# cslr_edc register map
Vendor: Texas Instruments
Peripheral module from a debugger description file.
Registers are 32-bit, read-only, reset 0x0 unless marked. A register's access mark holds for its fields unless they carry their own. Offsets are as the file gives them; lines under a group give offsets from that group; [hi:lo] are bit positions; {n}, {i} and the like mark numbered series; 'fields as' and 'values as' point back to an identical list; <NAME> marks a mode.

## EDC — Error Detection and Correction
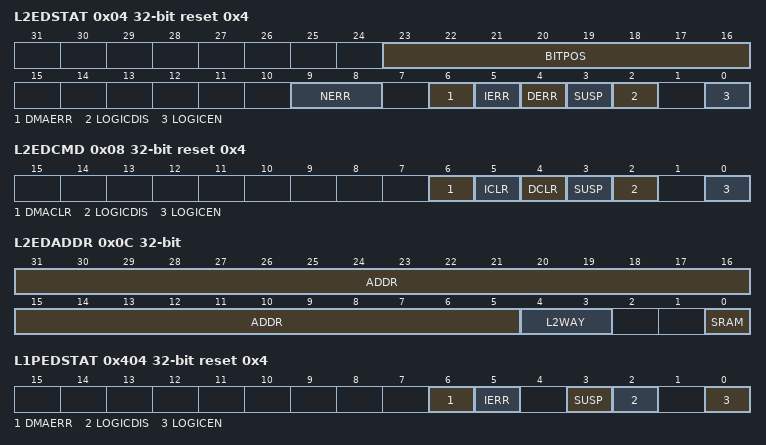
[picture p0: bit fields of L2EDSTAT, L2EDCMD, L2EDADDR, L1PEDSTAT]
0x04 L2EDSTAT reset 0x4 — L2 Error Detection Status Register
  [23:16] BITPOS — Position of single bit error 0 - 255
  [9:8] NERR — Number of bits in error
    0=1BIT (Single Bit Error); 1=2BIT (Double Bit Error); 3=PERROR (Error in the parity value (256-bit data is correct))
  [6] DMAERR — Parity error occurred during DMA Access?
    1=YES (Parity Error Occured during DMA Access); 0=NO (No Parity Error Occured during DMA Access)
  [5] IERR — Parity error occured during CPU/L1P access
    1=YES (Parity Error Occured during CPU/L1P Access); 0=NO (No Parity Error Occured during CPU/L1P Access)
  [4] DERR — Parity error occured during CPU/L1D data access
    1=YES (Parity Error Occured during CPU/L1D Data Access); 0=NO (No Parity Error Occured during CPU/L1D Data Access)
  [3] SUSP — EDC Parity generation logic suspended
    1=YES (EDC Logic Suspended?); 0=NO (EDC Logic Suspended?)
  [2] LOGICDIS — EDC Parity generation logic disable
    1=YES (EDC Logic Disabled); 0=NO (EDC Logic Disabled)
  [0] LOGICEN — EDC Parity generation logic enable
    1=YES (EDC Logic Enabled); 0=NO (EDC Logic Enabled)
0x08 L2EDCMD access per field reset 0x4 — L2 Error Detection Command Register
  [6] DMACLR wo — Clear Parity Error DMA Access Bit DMAERR
    1=CLR (Clear parity error CPU/L1P access bit IERR)
  [5] ICLR wo — Clear parity error CPU/L1P access bit IERR
    1=CLR (Clear parity error CPU/L1P access bit IERR)
  [4] DCLR wo — Clear CPU/L1D data access error bit DERR
    1=CLR (Clear parity error CPU/L1D data access bit DERR)
  [3] SUSP wo — Suspend EDC parity generation logic
    1=YES (Suspend EDC Logic)
  [2] LOGICDIS wo — Disable EDC parity generation logic
    1=YES (Disable EDC Logic)
  [0] LOGICEN wo — Enable EDC parity generation logic
    1=YES (Enable EDC Logic)
0x0C L2EDADDR — L2 Error Detection Address Register
  [31:5] ADDR — Address of the 256 bits in which a parity error occured (5 LSBs assumed to be 00000b)
  [4:3] L2WAY — The 'way' of L2 Cache the error occurred in.
    {v}=WAY{v} (v=0..3)
  [0] SRAM — Error Detected in L2 SRAM or L2 Cache
    0=L2CACHE (Error Detected in L2 Cache); 1=L2SRAM (Error Detected in L2 Memory)
0x10 L2EDEN0 rw — L2 Error Dection Enable Map 0 Register
  [31:0] EN — Enable Page 0 to 31 for L2 Error Detection UMAP0
    1=EN (Enable Page); 0=DIS (Disable Page)
0x14 L2EDEN1 rw — L2 Error Dection Enable Map 1 Register
  [31:0] EN — Enable Page 0 to 31 for L2 Error Detection UMAP1
    1=EN (Enable Page); 0=DIS (Disable Page)
0x18 L2EDCPEC access not given — L2 Error Detection - Correctable Parity Error Count
  [7:0] CNT — L2 EDC Correctable Error Count (access RC)
0x1C L2EDNPEC access not given — L2 Error Detection - Non-Correctable Parity Error Count
  [7:0] CNT — L2 EDC Non-Correctable Error Count (access RC)
0x404 L1PEDSTAT reset 0x4 — L1P Error Detection Status Register
  [6] DMAERR — Parity error occured during DMA Access to L1P SRAM
    1=YES (Parity Error Occured during DMA Access to L1P SRAM); 0=NO (No Parity Error Occured during DMA Access to L1P SRAM)
  [5] IERR — Parity error occured during program fetch
    1=YES (Parity Error Occured during Program Fetch); 0=NO (No Parity Error Occured during Program Fetch)
  [3] SUSP — EDC detection logic suspended
    1=YES (EDC Detection Logic Suspended?); 0=NO (EDCDetection Logic Suspended?)
  [2] LOGICDIS — EDC detection logic disabled
    1=YES (EDC Detection Logic Disabled); 0=NO (EDC Detection Logic Disabled)
  [0] LOGICEN — EDC detection logic enable
    1=YES (EDC Detection Logic Enabled); 0=NO (EDC Detection Logic Enabled)
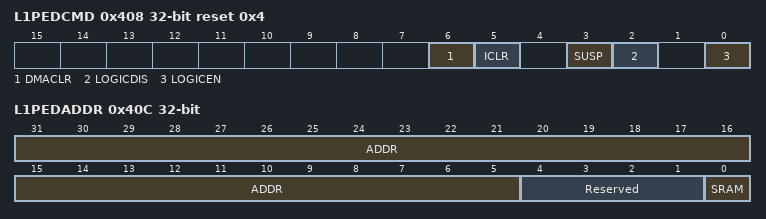
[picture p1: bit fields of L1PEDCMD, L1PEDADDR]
0x408 L1PEDCMD access per field reset 0x4 — L1P Error Detection Command Register
  [6] DMACLR wo — Clear Parity Error DMA Access Bit DMAERR
    1=CLR (Clear Parity Error CPU/L1P Access Bit IERR)
  [5] ICLR wo — Clear Program Fetch Parity Error Bit IERR
    1=CLR (Clear Program Fetch Parity Error Bit IERR)
  [3] SUSP wo — Suspend EDC Error Detect Logic
    1=YES (Suspend EDC Error Detect Logic)
  [2] LOGICDIS wo — Disable EDC Error Detect Logic
    1=YES (Disable EDC Error Detect Logic)
  [0] LOGICEN wo — Enable EDC Error Detect Logic
    1=YES (Enable EDC Error Detect Logic)
0x40C L1PEDADDR access not given — L1P Error Detection Address Register
  [31:5] ADDR ro — Address of the 256 bits in which a parity error occured (5 LSBs assumed to be 00000b)
  [4:1] Reserved — (access N)
  [0] SRAM ro — Error Detected in L1P SRAM or L1P Cache
    0=L1PCACHE (Error Detected in L1P Cache); 1=L1PSRAM (Error Detected in L1P Memory)
